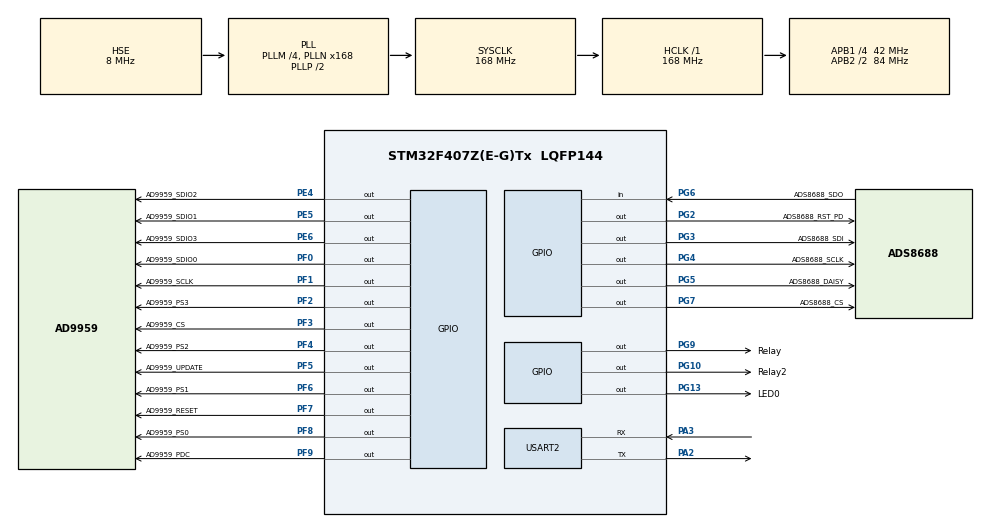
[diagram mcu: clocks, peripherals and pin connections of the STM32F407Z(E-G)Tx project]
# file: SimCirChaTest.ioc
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Mcu.Family=STM32F4
Mcu.Name=STM32F407Z(E-G)Tx
Mcu.Package=LQFP144
NVIC.PriorityGroup=NVIC_PRIORITYGROUP_4
NVIC.TIM3_IRQn=true\:0\:0\:true\:false\:true\:true\:true\:true
NVIC.USART2_IRQn=true\:1\:0\:true\:false\:false\:true\:true\:true
PA13.Mode=Serial_Wire
PA13.Signal=SYS_JTMS-SWDIO
PA14.Mode=Serial_Wire
PA14.Signal=SYS_JTCK-SWCLK
PA2.Mode=Asynchronous
PA2.Signal=USART2_TX
PA3.Mode=Asynchronous
PA3.Signal=USART2_RX
PC14-OSC32_IN.Mode=LSE-External-Oscillator
PC14-OSC32_IN.Signal=RCC_OSC32_IN
PC15-OSC32_OUT.Mode=LSE-External-Oscillator
PC15-OSC32_OUT.Signal=RCC_OSC32_OUT
PE4.GPIO_Label=AD9959_SDIO2
PE4.GPIO_Speed=GPIO_SPEED_FREQ_HIGH
PE4.Signal=GPIO_Output
PE5.GPIO_Label=AD9959_SDIO1
PE5.GPIO_Speed=GPIO_SPEED_FREQ_HIGH
PE5.Signal=GPIO_Output
PE6.GPIO_Label=AD9959_SDIO3
PE6.GPIO_Speed=GPIO_SPEED_FREQ_HIGH
PE6.Signal=GPIO_Output
PF0.GPIO_Label=AD9959_SDIO0
PF0.GPIO_Speed=GPIO_SPEED_FREQ_HIGH
PF0.Signal=GPIO_Output
PF1.GPIO_Label=AD9959_SCLK
PF1.GPIO_Speed=GPIO_SPEED_FREQ_HIGH
PF1.Signal=GPIO_Output
PF2.GPIO_Label=AD9959_PS3
PF2.GPIO_Speed=GPIO_SPEED_FREQ_HIGH
PF2.Signal=GPIO_Output
PF3.GPIO_Label=AD9959_CS
PF3.GPIO_Speed=GPIO_SPEED_FREQ_HIGH
PF3.Signal=GPIO_Output
PF4.GPIO_Label=AD9959_PS2
PF4.GPIO_Speed=GPIO_SPEED_FREQ_HIGH
PF4.Signal=GPIO_Output
PF5.GPIO_Label=AD9959_UPDATE
PF5.GPIO_Speed=GPIO_SPEED_FREQ_HIGH
PF5.Signal=GPIO_Output
PF6.GPIO_Label=AD9959_PS1
PF6.GPIO_Speed=GPIO_SPEED_FREQ_HIGH
PF6.Signal=GPIO_Output
PF7.GPIO_Label=AD9959_RESET
PF7.GPIO_Speed=GPIO_SPEED_FREQ_HIGH
PF7.Signal=GPIO_Output
PF8.GPIO_Label=AD9959_PS0
PF8.GPIO_Speed=GPIO_SPEED_FREQ_HIGH
PF8.Signal=GPIO_Output
PF9.GPIO_Label=AD9959_PDC
PF9.GPIO_Speed=GPIO_SPEED_FREQ_HIGH
PF9.Signal=GPIO_Output
PG10.GPIO_Label=Relay2
PG10.Signal=GPIO_Output
PG13.GPIO_Label=LED0
PG13.Signal=GPIO_Output
PG2.GPIO_Label=ADS8688_RST_PD
PG2.GPIO_Speed=GPIO_SPEED_FREQ_HIGH
PG2.Signal=GPIO_Output
PG3.GPIO_Label=ADS8688_SDI
PG3.GPIO_Speed=GPIO_SPEED_FREQ_HIGH
PG3.Signal=GPIO_Output
PG4.GPIO_Label=ADS8688_SCLK
PG4.GPIO_Speed=GPIO_SPEED_FREQ_HIGH
PG4.Signal=GPIO_Output
PG5.GPIO_Label=ADS8688_DAISY
PG5.GPIO_Speed=GPIO_SPEED_FREQ_HIGH
PG5.Signal=GPIO_Output
PG6.GPIO_Label=ADS8688_SDO
PG6.Signal=GPIO_Input
PG7.GPIO_Label=ADS8688_CS
PG7.GPIO_Speed=GPIO_SPEED_FREQ_HIGH
PG7.Signal=GPIO_Output
PG9.GPIO_Label=Relay
PG9.Signal=GPIO_Output
PH0-OSC_IN.Mode=HSE-External-Oscillator
PH0-OSC_IN.Signal=RCC_OSC_IN
PH1-OSC_OUT.Mode=HSE-External-Oscillator
PH1-OSC_OUT.Signal=RCC_OSC_OUT
ProjectManager.HeapSize=0x200
ProjectManager.StackSize=0x400
ProjectManager.TargetToolchain=STM32CubeIDE
RCC.48MHZClocksFreq_Value=84000000
RCC.AHBFreq_Value=168000000
RCC.APB1CLKDivider=RCC_HCLK_DIV4
RCC.APB1Freq_Value=42000000
RCC.APB1TimFreq_Value=84000000
RCC.APB2CLKDivider=RCC_HCLK_DIV2
RCC.APB2Freq_Value=84000000
RCC.APB2TimFreq_Value=168000000
RCC.CortexFreq_Value=168000000
RCC.HCLKFreq_Value=168000000
RCC.HSE_VALUE=8000000
RCC.HSI_VALUE=16000000
RCC.PLLM=4
RCC.PLLN=168
RCC.PLLSourceVirtual=RCC_PLLSOURCE_HSE
RCC.SYSCLKFreq_VALUE=168000000
RCC.SYSCLKSource=RCC_SYSCLKSOURCE_PLLCLK
RCC.VCOOutputFreq_Value=336000000
STMicroelectronics.X-CUBE-ALGOBUILD.1.3.0.LibraryCcDSPOoLibraryJjDSPOoLibrary=true
TIM3.AutoReloadPreload=TIM_AUTORELOAD_PRELOAD_ENABLE
TIM3.Period=328-1
TIM3.Prescaler=50-1
USART2.VirtualMode=VM_ASYNC
VP_STMicroelectronics.X-CUBE-ALGOBUILD_VS_DSPOoLibraryJjLibrary_1.3.0_1.3.0.Mode=DSPOoLibraryJjLibrary
VP_TIM3_VS_ClockSourceINT.Mode=Internal
board=custom

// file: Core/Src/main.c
/* USER CODE BEGIN Header */
/**
  ******************************************************************************
  * @file           : main.c
  * @brief          : Main program body
  ******************************************************************************
  * @attention
  *
  * Copyright (c) 2022 STMicroelectronics.
  * All rights reserved.
  *
  * This software is licensed under terms that can be found in the LICENSE file
  * in the root directory of this software component.
  * If no LICENSE file comes with this software, it is provided AS-IS.
  *
  ******************************************************************************
  */
/* USER CODE END Header */
#include "main.h"
#include "tim.h"
#include "usart.h"
#include "gpio.h"

/* USER CODE BEGIN Includes */
#include "algorithm.h"
#include "base.h"
#include "ADS8688.h"
#include "AD9959.h"
#include "cmd_process.h"
#include "hmi_user_uart.h"
/* USER CODE END Includes */

void SystemClock_Config(void);

int main(void)
{

  /* MCU Configuration--------------------------------------------------------*/

  /* Reset of all peripherals, Initializes the Flash interface and the Systick. */
  HAL_Init();

  /* Configure the system clock */
  SystemClock_Config();

  /* Initialize all configured peripherals */
  MX_GPIO_Init();
  MX_USART2_UART_Init();
  MX_TIM3_Init();
  /* USER CODE BEGIN 2 */
  delay_init(168);
  Params_Init();
  TFT_Init();			//串口屏初始化
  ADS8688_Init_Mult();//初始化ADS8688
  ad9959_init();		//初始化AD9959
//  getADResults();
  /* USER CODE END 2 */

  /* Infinite loop */
  while (1)
  {

    /* USER CODE BEGIN 3 */
//	  PrepareForTest();				//准备阶段：频率初始化，并选择合适的幅值

//	  if(sys.mode == BaseTest){		//基础部分测试
//		  /* 六路AD采集 */
//		  CalCircuitParam(&sys);
//		  /* 电路参数显示 */
//		  //显示输入阻抗，输入阻抗，增益
//          if(sys.inputRes < 1000)
//                SetTFTText(0,7,"%.3fΩ",sys.inputRes);
//          else
//                SetTFTText(0,7,"%.3fkΩ",sys.inputRes*0.001f);
//          if(sys.outputRes < 1000)
//                SetTFTText(0,8,"%.3fΩ",sys.outputRes);
//          else
//                SetTFTText(0,8,"%.3fkΩ",sys.outputRes*0.001f);
//          SetTFTText(0,9,"%.2f",sys.gain);
//
////          CheckAmp(0);
//		  CheckAmp(2);
//		  if(sys.AmpFreqFlag){
//			  relay2Load;
//			  SweepTest();			//扫频测试
//			  sys.AmpFreqFlag=0;
//			  relay2NoLoad;
//		  }
//		  else{
//			  delay_ms(1000);
//		  }
//	  }
//
//	  else if(sys.mode == UpTest){		//发挥部分测试
//		  CircuitFaultShow(CalCircuitError());
//	  }
//
//	  else if(sys.mode == ExAmpFreq){		//扩展幅频特性测试
//		  relay2Load;
//		  ExSweepTest();
//		  relay2NoLoad;
//	  }
//
//	  else if(sys.mode == ExElecTest){		//扩展电路故障部分测试
//		  ExCircuitFaultShow(CalCircuitError());
//	  }
  }
  /* USER CODE END 3 */
}

void SystemClock_Config(void)
{
  RCC_OscInitTypeDef RCC_OscInitStruct = {0};
  RCC_ClkInitTypeDef RCC_ClkInitStruct = {0};

  /** Configure the main internal regulator output voltage
  */
  __HAL_RCC_PWR_CLK_ENABLE();
  __HAL_PWR_VOLTAGESCALING_CONFIG(PWR_REGULATOR_VOLTAGE_SCALE1);

  /** Initializes the RCC Oscillators according to the specified parameters
  * in the RCC_OscInitTypeDef structure.
  */
  RCC_OscInitStruct.OscillatorType = RCC_OSCILLATORTYPE_HSE;
  RCC_OscInitStruct.HSEState = RCC_HSE_ON;
  RCC_OscInitStruct.PLL.PLLState = RCC_PLL_ON;
  RCC_OscInitStruct.PLL.PLLSource = RCC_PLLSOURCE_HSE;
  RCC_OscInitStruct.PLL.PLLM = 4;
  RCC_OscInitStruct.PLL.PLLN = 168;
  RCC_OscInitStruct.PLL.PLLP = RCC_PLLP_DIV2;
  RCC_OscInitStruct.PLL.PLLQ = 4;
  if (HAL_RCC_OscConfig(&RCC_OscInitStruct) != HAL_OK)
  {
    Error_Handler();
  }

  /** Initializes the CPU, AHB and APB buses clocks
  */
  RCC_ClkInitStruct.ClockType = RCC_CLOCKTYPE_HCLK|RCC_CLOCKTYPE_SYSCLK
                              |RCC_CLOCKTYPE_PCLK1|RCC_CLOCKTYPE_PCLK2;
  RCC_ClkInitStruct.SYSCLKSource = RCC_SYSCLKSOURCE_PLLCLK;
  RCC_ClkInitStruct.AHBCLKDivider = RCC_SYSCLK_DIV1;
  RCC_ClkInitStruct.APB1CLKDivider = RCC_HCLK_DIV4;
  RCC_ClkInitStruct.APB2CLKDivider = RCC_HCLK_DIV2;

  if (HAL_RCC_ClockConfig(&RCC_ClkInitStruct, FLASH_LATENCY_5) != HAL_OK)
  {
    Error_Handler();
  }
}

void Error_Handler(void)
{
  __disable_irq();
  while (1)
  {
  }
}
